# EPWM2_EPWM register map
Vendor: Texas Instruments
Peripheral module from a debugger description file (folder am243x).
Registers are 16-bit, read-write, reset 0x0 unless marked. A register's access mark holds for its fields unless they carry their own. Offsets are as the file gives them; lines under a group give offsets from that group; [hi:lo] are bit positions; {n}, {i} and the like mark numbered series; 'fields as' and 'values as' point back to an identical list; <NAME> marks a mode.

## EPWM2_EPWM
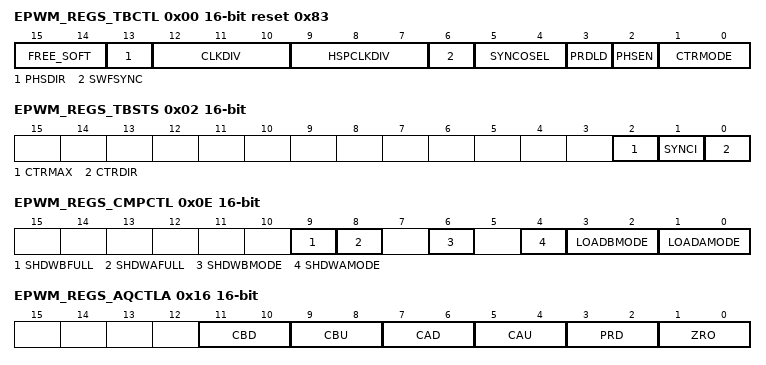
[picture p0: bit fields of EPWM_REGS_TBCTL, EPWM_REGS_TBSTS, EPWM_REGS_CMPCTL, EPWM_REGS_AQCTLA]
0x00 EPWM_REGS_TBCTL reset 0x83 — Time-Base Control Register
  [15:14] FREE_SOFT — Emulation Mode Bits These bits select the behavior of the ePWM time-base counter during emulation events:
  [13] PHSDIR — Phase Direction Bit This bit is only used when the time-base counter is configured in the up-down-count mode The PHSDIR bit indicates the direction the time-base counter [TBCNT] will count after a synchronization event occurs and a new phase value is loaded from the phase [TBPHS] register This is irrespective of the direction of the counter before the synchronization event In the up-count and down-count modes this bit is ignored
  [12:10] CLKDIV — Time-base Clock Prescale Bits These bits determine part of the time-base clock prescale value TBCLK = SYSCLKOUT/[HSPCLKDIV - CLKDIV]
  [9:7] HSPCLKDIV — High-Speed Time-base Clock Prescale Bits These bits determine part of the time-base clock prescale value TBCLK = SYSCLKOUT/[HSPCLKDIV - CLKDIV] This divisor emulates the HSPCLK in the TMS320x281x system as used on the Event Manager [EV] peripheral
  [6] SWFSYNC — Software Forced Synchronization Pulse
  [5:4] SYNCOSEL — Synchronization Output Select These bits select the source of the EPWMxSYNCO signal
  [3] PRDLD — Active Period Register Load From Shadow Register Select
  [2] PHSEN — Counter Register Load From Phase Register Enable
  [1:0] CTRMODE — Counter Mode The time-base counter mode is normally configured once and not changed during normal operation If you change the mode of the counter, the change will take effect at the next TBCLK edge and the current counter value shall increment or decrement from the value before the mode change These bits set the time-base counter mode of operation as follows:
0x02 EPWM_REGS_TBSTS access not given — Time-Base Status Register
  [2] CTRMAX — Time-Base Counter Max Latched Status Bit (access R/W1TC)
  [1] SYNCI — Input Synchronization Latched Status Bit (access R/W1TC)
  [0] CTRDIR ro — Time-Base Counter Direction Status Bit At reset, the counter is frozen, therefore, this bit has no meaning To make this bit meaningful, you must first set the appropriate mode via TBCTL[CTRMODE]
0x04 EPWM_REGS_TBPHSHR — Time Base Phase High Resolution Register
  [15:8] TBPHSH — Time-base phase high-resolution bits
0x06 EPWM_REGS_TBPHS — Time Base Phase Register. This register is only available on ePWM instances that include the high-resolution PWM (HRPWM) extension, otherwise, this location is reserved.
  [15:0] TBPHS — These bits set time-base counter phase of the selected ePWM relative to the time-base that is supplying the synchronization input signal [a] If TBCTL[PHSEN] = 0, then the synchronization event is ignored and the time-base counter is not loaded with the phase [b] If TBCTL[PHSEN] = 1, then the time-base counter [TBCNT] will be loaded with the phase [TBPHS] when a synchronization event occurs The synchronization event can be initiated by the input synchronization signal [EPWMxSYNCI] or by a software forced synchronization
0x08 EPWM_REGS_TBCNT — Time Base Counter Register
  [15:0] TBCNT — Reading these bits gives the current time-base counter value Writing to these bits sets the current time-base counter value The update happens as soon as the write occurs The write is NOT synchronized to the time-base clock [TBCLK] and the register is not shadowed
0x0A EPWM_REGS_TBPRD — Time Base Period Register
  [15:0] TBPRD — These bits determine the period of the time-base counter This sets the PWM frequency Shadowing of this register is enabled and disabled by the TBCTL[PRDLD] bit By default this register is shadowed [a] If TBCTL[PRDLD] = 0, then the shadow is enabled and any write or read will automatically go to the shadow register In this case, the active register will be loaded from the shadow register when the time-base counter equals zero [b] If TBCTL[PRDLD] = 1, then the shadow is disabled and any write or read will go directly to the active register, that is the register actively controlling the hardware [c] The active and shadow registers share the same memory map address
0x0E EPWM_REGS_CMPCTL access per field — Counter Compare Control Register
  [9] SHDWBFULL ro — Counter-compare B [CMPB] Shadow Register Full Status Flag This bit self clears once a load-strobe occurs
  [8] SHDWAFULL ro — Counter-compare A [CMPA] Shadow Register Full Status Flag The flag bit is set when a 32 bit write to CMPA:CMPAHR register or a 16 bit write to CMPA register is made A 16 bit write to CMPAHR register will not affect the flag This bit self clears once a load-strobe occurs
  [6] SHDWBMODE rw — Counter-compare B [CMPB] Register Operating Mode
  [4] SHDWAMODE rw — Counter-compare A [CMPA] Register Operating Mode
  [3:2] LOADBMODE rw — Active Counter-Compare B [CMPB] Load From Shadow Select Mode This bit has no effect in immediate mode [CMPCTL[SHDWBMODE] = 1]
  [1:0] LOADAMODE rw — Active Counter-Compare A [CMPA] Load From Shadow Select Mode This bit has no effect in immediate mode [CMPCTL[SHDWAMODE] = 1]
0x10 EPWM_REGS_CMPAHR — Counter Compare A High Resolution Register. This register is only available on ePWM instances that include the high-resolution PWM (HRPWM) extension; otherwise, this location is reserved.
  [15:8] CMPAHR — Compare A High-Resolution register bits for MEP step control A minimum value of 1h is needed to enable HRPWM capabilities Valid MEP range of operation 1-255h
0x12 EPWM_REGS_CMPA — Counter Compare A Register
  [15:0] CMPA — The value in the active CMPA register is continuously compared to the time-base counter [TBCNT] When the values are equal, the counter-compare module generates a time-base counter equal to counter compare A event This event is sent to the action-qualifier where it is qualified and converted it into one or more actions These actions can be applied to either the EPWMxA or the EPWMxB output depending on the configuration of the AQCTLA and AQCTLB registers The actions that can be defined in the AQCTLA and AQCTLB registers include the following [a] Do nothing the event is ignored [b] Clear: Pull the EPWMxA and/or EPWMxB signal low [c] Set: Pull the EPWMxA and/or EPWMxB signal high [d] Toggle the EPWMxA and/or EPWMxB signal Shadowing of this register is enabled and disabled by the CMPCTL[SHDWAMODE] bit By default this register is shadowed [a] If CMPCTL[SHDWAMODE] = 0, then the shadow is enabled and any write or read will automatically go to the shadow register In this case, the CMPCTL[LOADAMODE] bit field determines which event will load the active register from the shadow register [b] Before a write, the CMPCTL[SHDWAFULL] bit can be read to determine if the shadow register is currently full [c] If CMPCTL[SHDWAMODE] = 1, then the shadow register is disabled and any write or read will go directly to the active register, that is the register actively controlling the hardware [d] In either mode, the active and shadow registers share the same memory map address
0x14 EPWM_REGS_CMPB — Counter Compare B Register
  [15:0] CMPB — The value in the active CMPB register is continuously compared to the time-base counter [TBCNT] When the values are equal, the counter-compare module generates a time-base counter equal to counter compare B event This event is sent to the action-qualifier where it is qualified and converted it into one or more actions These actions can be applied to either the EPWMxA or the EPWMxB output depending on the configuration of the AQCTLA and AQCTLB registers The actions that can be defined in the AQCTLA and AQCTLB registers include the following [a] Do nothing, the event is ignored [b] Clear: Pull the EPWMxA and/or EPWMxB signal low [c] Set: Pull the EPWMxA and/or EPWMxB signal high [d] Toggle the EPWMxA and/or EPWMxB signal Shadowing of this register is enabled and disabled by the CMPCTL[SHDWBMODE] bit By default this register is shadowed [a] If CMPCTL[SHDWBMODE] = 0, then the shadow is enabled and any write or read will automatically go to the shadow register In this case, the CMPCTL[LOADBMODE] bit field determines which event will load the active register from the shadow register: [b] Before a write, the CMPCTL[SHDWBFULL] bit can be read to determine if the shadow register is currently full [c] If CMPCTL[SHDWBMODE] = 1, then the shadow register is disabled and any write or read will go directly to the active register, that is the register actively controlling the hardware [d] In either mode, the active and shadow registers share the same memory map address
0x16 EPWM_REGS_AQCTLA — Action Qualifier Control Register For Output A
  [11:10] CBD — Action when the time-base counter equals the active CMPB register and the counter is decrementing
  [9:8] CBU — Action when the counter equals the active CMPB register and the counter is incrementing
  [7:6] CAD — Action when the counter equals the active CMPA register and the counter is decrementing
  [5:4] CAU — Action when the counter equals the active CMPA register and the counter is incrementing
  [3:2] PRD — Action when the counter equals the period Note: By definition, in count up-down mode when the counter equals period the direction is defined as 0 or counting down
  [1:0] ZRO — Action when counter equals zero Note: By definition, in count up-down mode when the counter equals 0 the direction is defined as 1 or counting up
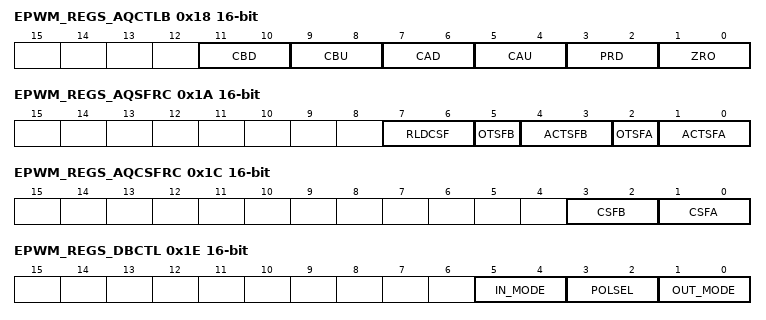
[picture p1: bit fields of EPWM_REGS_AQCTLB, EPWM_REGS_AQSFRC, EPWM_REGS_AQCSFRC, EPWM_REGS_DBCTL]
0x18 EPWM_REGS_AQCTLB — Action Qualifier Control Register For Output B
  [11:10] CBD — Action when the counter equals the active CMPB register and the counter is decrementing
  [9:8] CBU — Action when the counter equals the active CMPB register and the counter is incrementing
  [7:6] CAD — Action when the counter equals the active CMPA register and the counter is decrementing
  [5:4] CAU — Action when the counter equals the active CMPA register and the counter is incrementing
  [3:2] PRD — Action when the counter equals the period Note: By definition, in count up-down mode when the counter equals period the direction is defined as 0 or counting down
  [1:0] ZRO — Action when counter equals zero Note: By definition, in count up-down mode when the counter equals 0 the direction is defined as 1 or counting up
0x1A EPWM_REGS_AQSFRC access not given — Action Qualifier Software Force Register
  [7:6] RLDCSF rw — AQCSFRC Active Register Reload From Shadow Options
  [5] OTSFB — One-Time Software Forced Event on Output B (access R/W1TC)
  [4:3] ACTSFB rw — Action when One-Time Software Force B Is invoked
  [2] OTSFA — One-Time Software Forced Event on Output A (access R/W1TC)
  [1:0] ACTSFA rw — Action When One-Time Software Force A Is Invoked
0x1C EPWM_REGS_AQCSFRC — Action Qualifier Continuous S/W Force Register
  [3:2] CSFB — Continuous Software Force on Output B In immediate mode, a continuous force takes effect on the next TBCLK edge In shadow mode, a continuous force takes effect on the next TBCLK edge after a shadow load into the active register To configure shadow mode, use AQSFRC[RLDCSF]
  [1:0] CSFA — Continuous Software Force on Output A In immediate mode, a continuous force takes effect on the next TBCLK edge In shadow mode, a continuous force takes effect on the next TBCLK edge after a shadow load into the active register
0x1E EPWM_REGS_DBCTL — Dead-Band Generator Control Register
  [5:4] IN_MODE — Dead Band Input Mode Control Bit 5 controls the S5 switch and bit 4 controls the S4 switch This allows you to select the input source to the falling-edge and rising-edge delay To produce classical dead-band waveforms, the default is EPWMxA In is the source for both falling and rising-edge delays
  [3:2] POLSEL — Polarity Select Control Bit 3 controls the S3 switch and bit 2 controls the S2 switch This allows you to selectively invert one of the delayed signals before it is sent out of the dead-band submodule The following descriptions correspond to classical upper/lower switch control as found in one leg of a digital motor control inverter These assume that DBCTL[OUT_MODE] = 1,1 and DBCTL[IN_MODE] = 0,0 Other enhanced modes are also possible, but not regarded as typical usage modes
  [1:0] OUT_MODE — Dead-band Output Mode Control Bit 1 controls the S1 switch and bit 0 controls the S0 switch This allows you to selectively enable or bypass the dead-band generation for the falling-edge and rising-edge delay
0x20 EPWM_REGS_DBRED — Dead-Band Generator Rising Edge Delay Count Register
  [9:0] DEL — Rising Edge Delay Count 10 bit counter
0x22 EPWM_REGS_DBFED — Dead-Band Generator Falling Edge Delay Count Register
  [9:0] DEL — Falling Edge Delay Count 10 bit counter
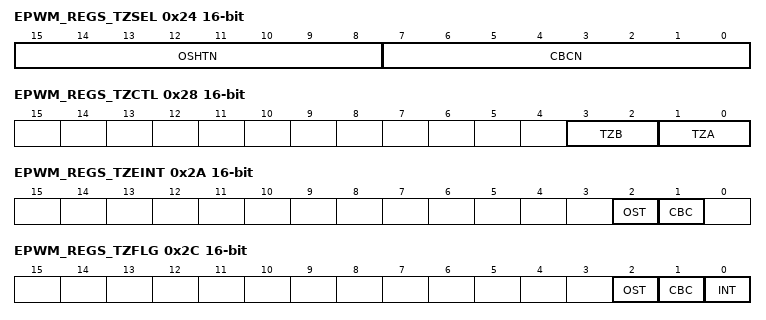
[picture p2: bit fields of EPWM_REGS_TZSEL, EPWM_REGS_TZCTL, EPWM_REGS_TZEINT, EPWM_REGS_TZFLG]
0x24 EPWM_REGS_TZSEL — Trip Zone Select Register
  [15:8] OSHTN — Trip-zone n [TZn] select One-Shot [OSHT] trip-zone enable/disable When any of the enabled pins go low, a one-shot trip event occurs for this ePWM module When the event occurs, the action defined in the TZCTL register is taken on the EPWMxA and EPWMxB outputs The one-shot trip condition remains latched until you clear the condition via the TZCLR register
  [7:0] CBCN — Trip-zone n [TZn] select Cycle-by-Cycle [CBC] trip-zone enable/disable When any of the enabled pins go low, a cycle-by-cycle trip event occurs for this ePWM module When the event occurs, the action defined in the TZCTL register is taken on the EPWMxA and EPWMxB outputs A cycle-by-cycle trip condition is automatically cleared when the time-base counter reaches zero
0x28 EPWM_REGS_TZCTL — Trip Zone Control Register
  [3:2] TZB — When a trip event occurs the following action is taken on output EPWMxB Which trip-zone pins can cause an event is defined in the TZSEL register
  [1:0] TZA — When a trip event occurs the following action is taken on output EPWMxA Which trip-zone pins can cause an event is defined in the TZSEL register
0x2A EPWM_REGS_TZEINT — Trip Zone Enable Interrupt Register
  [2] OST — Trip-zone One-Shot Interrupt Enable
  [1] CBC — Trip-zone Cycle-by-Cycle Interrupt Enable
0x2C EPWM_REGS_TZFLG ro — Trip Zone Flag Register
  [2] OST — Latched Status Flag for A One-Shot Trip Event
  [1] CBC — Latched Status Flag for Cycle-By-Cycle Trip Event
  [0] INT — Latched Trip Interrupt Status Flag
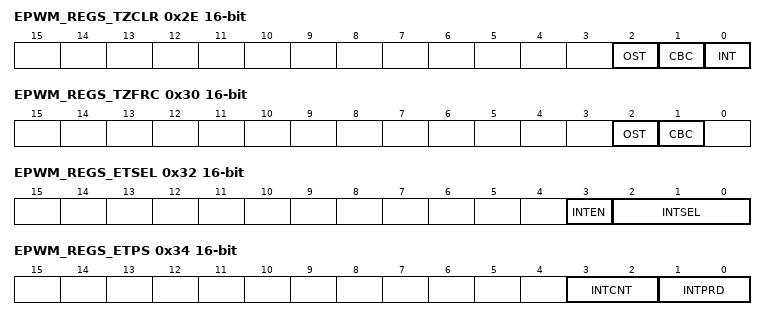
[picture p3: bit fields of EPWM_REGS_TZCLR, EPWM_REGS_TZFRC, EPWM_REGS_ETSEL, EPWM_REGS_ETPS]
0x2E EPWM_REGS_TZCLR — Trip Zone Clear Register
  [2] OST — Clear Flag for One-Shot Trip [OST] Latch
  [1] CBC — Clear Flag for Cycle-By-Cycle [CBC] Trip Latch
  [0] INT — Global Interrupt Clear Flag
0x30 EPWM_REGS_TZFRC — Trip Zone Force Register
  [2] OST — Force a One-Shot Trip Event via Software
  [1] CBC — Force a Cycle-by-Cycle Trip Event via Software
0x32 EPWM_REGS_ETSEL — Event Trigger Selection Register
  [3] INTEN — Enable ePWM Interrupt [EPWMx_INT] Generation
  [2:0] INTSEL — ePWM Interrupt [EPWMx_INT] Selection Options
0x34 EPWM_REGS_ETPS access per field — Event Trigger Pre-Scale Register
  [3:2] INTCNT ro — ePWM Interrupt Event [EPWMx_INT] Counter Register These bits indicate how many selected ETSEL[INTSEL] events have occurred These bits are automatically cleared when an interrupt pulse is generated If interrupts are disabled, ETSEL[INT] = 0 or the interrupt flag is set, ETFLG[INT] = 1, the counter will stop counting events when it reaches the period value ETPS[INTCNT] = ETPS[INTPRD]
  [1:0] INTPRD rw — ePWM Interrupt [EPWMx_INT] Period Select These bits determine how many selected ETSEL[INTSEL] events need to occur before an interrupt is generated To be generated, the interrupt must be enabled [ETSEL[INT] = 1] If the interrupt status flag is set from a previous interrupt [ETFLG[INT] = 1] then no interrupt will be generated until the flag is cleared via the ETCLR[INT] bit This allows for one interrupt to be pending while another is still being serviced Once the interrupt is generated, the ETPS[INTCNT] bits will automatically be cleared Writing a INTPRD value that is the same as the current counter value will trigger an interrupt if it is enabled and the status flag is clear Writing a INTPRD value that is less than the current counter value will result in an undefined state If a counter event occurs at the same instant as a new zero or non-zero INTPRD value is written, the counter is incremented
0x36 EPWM_REGS_ETFLG ro — Event Trigger Flag Register
  [0] INT — Latched ePWM Interrupt [EPWMx_INT] Status Flag
0x38 EPWM_REGS_ETCLR ro — Event Trigger Clear Register
  [0] INT — ePWM Interrupt [EPWMx_INT] Flag Clear Bit
0x3A EPWM_REGS_ETFRC ro — Event Trigger Force Register
  [0] INT — INT Force Bit The interrupt will only be generated if the event is enabled in the ETSEL register The INT flag bit will be set regardless
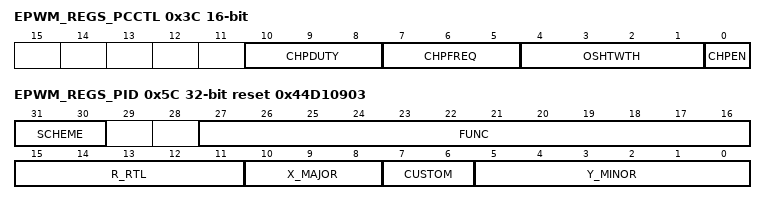
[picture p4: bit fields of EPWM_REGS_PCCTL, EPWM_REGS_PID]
0x3C EPWM_REGS_PCCTL — PWM Chopper Control Register
  [10:8] CHPDUTY — Chopping Clock Duty Cycle
  [7:5] CHPFREQ — Chopping Clock Frequency
  [4:1] OSHTWTH — One-Shot Pulse Width
  [0] CHPEN — PWM-chopping Enable
0x5C EPWM_REGS_PID 32-bit ro reset 0x44D10903 — EHRPWM Peripheral ID Register. The IP revision register is used by software to track features, bugs, and compatibility.
  [31:30] SCHEME — Used to distinguish between the old scheme and current
  [27:16] FUNC
  [15:11] R_RTL — RTL version [R], maintained by IP design owner
  [10:8] X_MAJOR — Major revision [X]
  [7:6] CUSTOM
  [5:0] Y_MINOR — Minor revision [Y]
